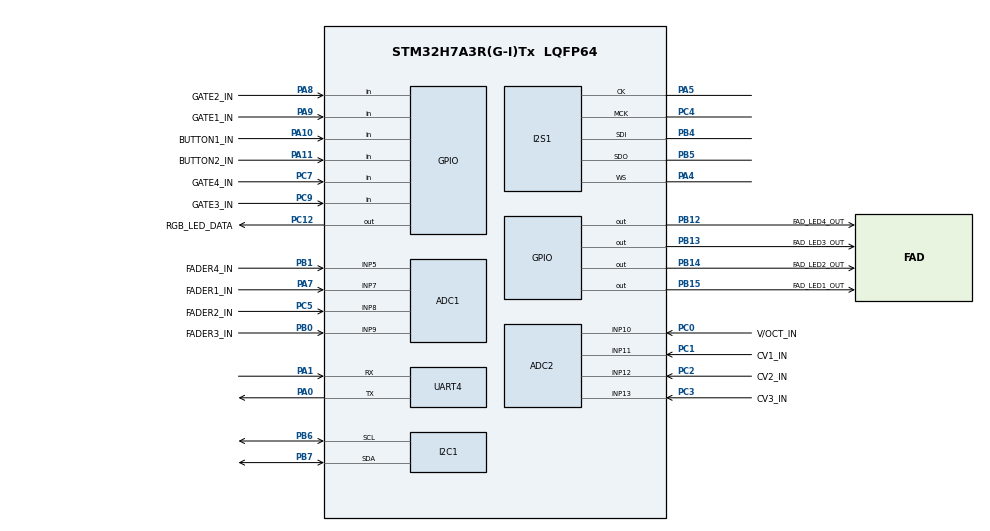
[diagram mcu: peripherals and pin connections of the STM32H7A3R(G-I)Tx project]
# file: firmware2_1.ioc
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ADC1.Channel-1\#ChannelRegularConversion=ADC_CHANNEL_7
ADC1.Channel-2\#ChannelRegularConversion=ADC_CHANNEL_8
ADC1.Channel-3\#ChannelRegularConversion=ADC_CHANNEL_9
ADC1.Channel-4\#ChannelRegularConversion=ADC_CHANNEL_5
ADC1.ClockPrescaler=ADC_CLOCK_ASYNC_DIV4
ADC1.ContinuousConvMode=ENABLE
ADC1.NbrOfConversion=4
ADC1.NbrOfConversionFlag=1
ADC1.OffsetNumber-1\#ChannelRegularConversion=ADC_OFFSET_NONE
ADC1.OffsetNumber-2\#ChannelRegularConversion=ADC_OFFSET_NONE
ADC1.OffsetNumber-3\#ChannelRegularConversion=ADC_OFFSET_NONE
ADC1.OffsetNumber-4\#ChannelRegularConversion=ADC_OFFSET_NONE
ADC1.OffsetSignedSaturation-1\#ChannelRegularConversion=DISABLE
ADC1.OffsetSignedSaturation-2\#ChannelRegularConversion=DISABLE
ADC1.OffsetSignedSaturation-3\#ChannelRegularConversion=DISABLE
ADC1.OffsetSignedSaturation-4\#ChannelRegularConversion=DISABLE
ADC1.Rank-1\#ChannelRegularConversion=1
ADC1.Rank-2\#ChannelRegularConversion=2
ADC1.Rank-3\#ChannelRegularConversion=3
ADC1.Rank-4\#ChannelRegularConversion=4
ADC1.SamplingTime-1\#ChannelRegularConversion=ADC_SAMPLETIME_1CYCLE_5
ADC1.SamplingTime-2\#ChannelRegularConversion=ADC_SAMPLETIME_1CYCLE_5
ADC1.SamplingTime-3\#ChannelRegularConversion=ADC_SAMPLETIME_1CYCLE_5
ADC1.SamplingTime-4\#ChannelRegularConversion=ADC_SAMPLETIME_1CYCLE_5
ADC1.master=1
ADC2.Channel-5\#ChannelRegularConversion=ADC_CHANNEL_10
ADC2.Channel-6\#ChannelRegularConversion=ADC_CHANNEL_11
ADC2.Channel-7\#ChannelRegularConversion=ADC_CHANNEL_12
ADC2.Channel-8\#ChannelRegularConversion=ADC_CHANNEL_13
ADC2.ContinuousConvMode=ENABLE
ADC2.NbrOfConversion=4
ADC2.NbrOfConversionFlag=1
ADC2.OffsetNumber-5\#ChannelRegularConversion=ADC_OFFSET_NONE
ADC2.OffsetNumber-6\#ChannelRegularConversion=ADC_OFFSET_NONE
ADC2.OffsetNumber-7\#ChannelRegularConversion=ADC_OFFSET_NONE
ADC2.OffsetNumber-8\#ChannelRegularConversion=ADC_OFFSET_NONE
ADC2.OffsetSignedSaturation-5\#ChannelRegularConversion=DISABLE
ADC2.OffsetSignedSaturation-6\#ChannelRegularConversion=DISABLE
ADC2.OffsetSignedSaturation-7\#ChannelRegularConversion=DISABLE
ADC2.OffsetSignedSaturation-8\#ChannelRegularConversion=DISABLE
ADC2.Rank-5\#ChannelRegularConversion=1
ADC2.Rank-6\#ChannelRegularConversion=2
ADC2.Rank-7\#ChannelRegularConversion=3
ADC2.Rank-8\#ChannelRegularConversion=4
ADC2.SamplingTime-5\#ChannelRegularConversion=ADC_SAMPLETIME_1CYCLE_5
ADC2.SamplingTime-6\#ChannelRegularConversion=ADC_SAMPLETIME_1CYCLE_5
ADC2.SamplingTime-7\#ChannelRegularConversion=ADC_SAMPLETIME_1CYCLE_5
ADC2.SamplingTime-8\#ChannelRegularConversion=ADC_SAMPLETIME_1CYCLE_5
CORTEX_M7.default_mode_Activation=1
Dma.ADC1.2.Direction=DMA_PERIPH_TO_MEMORY
Dma.ADC1.2.EventEnable=DISABLE
Dma.ADC1.2.FIFOMode=DMA_FIFOMODE_DISABLE
Dma.ADC1.2.Instance=DMA1_Stream2
Dma.ADC1.2.MemDataAlignment=DMA_MDATAALIGN_HALFWORD
Dma.ADC1.2.MemInc=DMA_MINC_ENABLE
Dma.ADC1.2.Mode=DMA_CIRCULAR
Dma.ADC1.2.PeriphDataAlignment=DMA_PDATAALIGN_HALFWORD
Dma.ADC1.2.PeriphInc=DMA_PINC_DISABLE
Dma.ADC1.2.Polarity=HAL_DMAMUX_REQ_GEN_RISING
Dma.ADC1.2.Priority=DMA_PRIORITY_LOW
Dma.ADC1.2.RequestNumber=1
Dma.ADC1.2.SignalID=NONE
Dma.ADC1.2.SyncEnable=DISABLE
Dma.ADC1.2.SyncPolarity=HAL_DMAMUX_SYNC_NO_EVENT
Dma.ADC1.2.SyncRequestNumber=1
Dma.ADC1.2.SyncSignalID=NONE
Dma.ADC2.3.Direction=DMA_PERIPH_TO_MEMORY
Dma.ADC2.3.EventEnable=DISABLE
Dma.ADC2.3.FIFOMode=DMA_FIFOMODE_DISABLE
Dma.ADC2.3.Instance=DMA1_Stream3
Dma.ADC2.3.MemDataAlignment=DMA_MDATAALIGN_HALFWORD
Dma.ADC2.3.MemInc=DMA_MINC_ENABLE
Dma.ADC2.3.Mode=DMA_NORMAL
Dma.ADC2.3.PeriphDataAlignment=DMA_PDATAALIGN_HALFWORD
Dma.ADC2.3.PeriphInc=DMA_PINC_DISABLE
Dma.ADC2.3.Polarity=HAL_DMAMUX_REQ_GEN_RISING
Dma.ADC2.3.Priority=DMA_PRIORITY_LOW
Dma.ADC2.3.RequestNumber=1
Dma.ADC2.3.SignalID=NONE
Dma.ADC2.3.SyncEnable=DISABLE
Dma.ADC2.3.SyncPolarity=HAL_DMAMUX_SYNC_NO_EVENT
Dma.ADC2.3.SyncRequestNumber=1
Dma.ADC2.3.SyncSignalID=NONE
Dma.Request0=SPI1_RX
Dma.Request1=SPI1_TX
Dma.Request2=ADC1
Dma.Request3=ADC2
Dma.SPI1_RX.0.Direction=DMA_PERIPH_TO_MEMORY
Dma.SPI1_RX.0.EventEnable=DISABLE
Dma.SPI1_RX.0.FIFOMode=DMA_FIFOMODE_DISABLE
Dma.SPI1_RX.0.Instance=DMA1_Stream0
Dma.SPI1_RX.0.MemDataAlignment=DMA_MDATAALIGN_HALFWORD
Dma.SPI1_RX.0.MemInc=DMA_MINC_ENABLE
Dma.SPI1_RX.0.Mode=DMA_NORMAL
Dma.SPI1_RX.0.PeriphDataAlignment=DMA_PDATAALIGN_HALFWORD
Dma.SPI1_RX.0.PeriphInc=DMA_PINC_DISABLE
Dma.SPI1_RX.0.Polarity=HAL_DMAMUX_REQ_GEN_RISING
Dma.SPI1_RX.0.Priority=DMA_PRIORITY_VERY_HIGH
Dma.SPI1_RX.0.RequestNumber=1
Dma.SPI1_RX.0.SignalID=NONE
Dma.SPI1_RX.0.SyncEnable=DISABLE
Dma.SPI1_RX.0.SyncPolarity=HAL_DMAMUX_SYNC_NO_EVENT
Dma.SPI1_RX.0.SyncRequestNumber=1
Dma.SPI1_RX.0.SyncSignalID=NONE
Dma.SPI1_TX.1.Direction=DMA_MEMORY_TO_PERIPH
Dma.SPI1_TX.1.EventEnable=DISABLE
Dma.SPI1_TX.1.FIFOMode=DMA_FIFOMODE_DISABLE
Dma.SPI1_TX.1.Instance=DMA1_Stream1
Dma.SPI1_TX.1.MemDataAlignment=DMA_MDATAALIGN_HALFWORD
Dma.SPI1_TX.1.MemInc=DMA_MINC_ENABLE
Dma.SPI1_TX.1.Mode=DMA_NORMAL
Dma.SPI1_TX.1.PeriphDataAlignment=DMA_PDATAALIGN_HALFWORD
Dma.SPI1_TX.1.PeriphInc=DMA_PINC_DISABLE
Dma.SPI1_TX.1.Polarity=HAL_DMAMUX_REQ_GEN_RISING
Dma.SPI1_TX.1.Priority=DMA_PRIORITY_VERY_HIGH
Dma.SPI1_TX.1.RequestNumber=1
Dma.SPI1_TX.1.SignalID=NONE
Dma.SPI1_TX.1.SyncEnable=DISABLE
Dma.SPI1_TX.1.SyncPolarity=HAL_DMAMUX_SYNC_NO_EVENT
Dma.SPI1_TX.1.SyncRequestNumber=1
Dma.SPI1_TX.1.SyncSignalID=NONE
FREERTOS.Tasks01=defaultTask,24,128,StartDefaultTask,Default,NULL,Dynamic,NULL,NULL
I2C1.Timing=0x109096E2
I2S1.ErrorAudioFreq=0.0 %
I2S1.Instance=SPI$Index
I2S1.RealAudioFreq=8.0 KHz
Mcu.Family=STM32H7
Mcu.Name=STM32H7A3R(G-I)Tx
Mcu.Package=LQFP64
NVIC.DMA1_Stream0_IRQn=true\:5\:0\:false\:false\:true\:true\:false\:true\:true
NVIC.DMA1_Stream1_IRQn=true\:5\:0\:false\:false\:true\:true\:false\:true\:true
NVIC.DMA1_Stream2_IRQn=true\:5\:0\:false\:false\:true\:true\:false\:true\:true
NVIC.DMA1_Stream3_IRQn=true\:5\:0\:false\:false\:true\:true\:false\:true\:true
NVIC.PriorityGroup=NVIC_PRIORITYGROUP_4
NVIC.TIM7_IRQn=true\:15\:0\:false\:false\:true\:false\:false\:true\:true
NVIC.TimeBase=TIM7_IRQn
NVIC.TimeBaseIP=TIM7
PA0.Mode=Asynchronous
PA0.Signal=UART4_TX
PA1.Mode=Asynchronous
PA1.Signal=UART4_RX
PA10.GPIO_Label=BUTTON1_IN
PA10.Signal=GPIO_Input
PA11.GPIO_Label=BUTTON2_IN
PA11.Signal=GPIO_Input
PA13.Mode=Trace_Asynchronous_SW
PA13.Signal=DEBUG_JTMS-SWDIO
PA14.Mode=Trace_Asynchronous_SW
PA14.Signal=DEBUG_JTCK-SWCLK
PA4.Mode=Full_Duplex_Master
PA4.Signal=I2S1_WS
PA5.Mode=Full_Duplex_Master
PA5.Signal=I2S1_CK
PA7.GPIO_Label=FADER1_IN
PA7.Signal=ADCx_INP7
PA8.GPIO_Label=GATE2_IN
PA8.Signal=GPIO_Input
PA9.GPIO_Label=GATE1_IN
PA9.Signal=GPIO_Input
PB0.GPIO_Label=FADER3_IN
PB0.Signal=ADCx_INP9
PB1.GPIO_Label=FADER4_IN
PB1.Signal=ADCx_INP5
PB12.GPIO_Label=FAD_LED4_OUT
PB12.Signal=GPIO_Output
PB13.GPIO_Label=FAD_LED3_OUT
PB13.Signal=GPIO_Output
PB14.GPIO_Label=FAD_LED2_OUT
PB14.Signal=GPIO_Output
PB15.GPIO_Label=FAD_LED1_OUT
PB15.Signal=GPIO_Output
PB3.Mode=Trace_Asynchronous_SW
PB3.Signal=DEBUG_JTDO-SWO
PB4.Mode=Full_Duplex_Master
PB4.Signal=I2S1_SDI
PB5.Mode=Full_Duplex_Master
PB5.Signal=I2S1_SDO
PB6.Mode=I2C
PB6.Signal=I2C1_SCL
PB7.Mode=I2C
PB7.Signal=I2C1_SDA
PC0.GPIO_Label=V/OCT_IN
PC0.Signal=ADCx_INP10
PC1.GPIO_Label=CV1_IN
PC1.Signal=ADCx_INP11
PC12.GPIO_Label=RGB_LED_DATA
PC12.Signal=GPIO_Output
PC2.GPIO_Label=CV2_IN
PC2.Signal=ADCx_INP12
PC3.GPIO_Label=CV3_IN
PC3.Signal=SharedAnalog_PC3
PC4.Mode=Master_Clock_Activated
PC4.Signal=I2S1_MCK
PC5.GPIO_Label=FADER2_IN
PC5.Signal=ADCx_INP8
PC7.GPIO_Label=GATE4_IN
PC7.Signal=GPIO_Input
PC9.GPIO_Label=GATE3_IN
PC9.Signal=GPIO_Input
PH0-OSC_IN.Mode=HSE-External-Oscillator
PH0-OSC_IN.Signal=RCC_OSC_IN
PH1-OSC_OUT.Mode=HSE-External-Oscillator
PH1-OSC_OUT.Signal=RCC_OSC_OUT
ProjectManager.HeapSize=0x200
ProjectManager.StackSize=0x400
ProjectManager.TargetToolchain=CMake
RCC.ADCFreq_Value=48000000
RCC.APB1Freq_Value=76800000
RCC.APB2Freq_Value=76800000
RCC.APB3Freq_Value=76800000
RCC.APB4Freq_Value=76800000
RCC.CDPPRE=RCC_APB3_DIV2
RCC.CDPPRE1=RCC_APB1_DIV2
RCC.CDPPRE2=RCC_APB2_DIV2
RCC.CortexFreq_Value=153600000
RCC.DIVM1=5
RCC.DIVM2=2
RCC.DIVM3=24
RCC.DIVN1=64
RCC.DIVN2=12
RCC.DIVP2=3
RCC.DIVQ1=25
RCC.DIVQ2=6
RCC.HCLKFreq_Value=153600000
RCC.PLL2FRACN=0
RCC.PLLFRACN=0
RCC.PLLSourceVirtual=RCC_PLLSOURCE_HSE
RCC.SRDPPRE=RCC_APB4_DIV2
RCC.SYSCLKFreq_VALUE=153600000
RCC.SYSCLKSource=RCC_SYSCLKSOURCE_PLLCLK
RCC.USBFreq_Value=12288000
SH.ADCx_INP10.0=ADC2_INP10,IN10-Single-Ended
SH.ADCx_INP11.0=ADC2_INP11,IN11-Single-Ended
SH.ADCx_INP12.0=ADC2_INP12,IN12-Single-Ended
SH.ADCx_INP5.0=ADC1_INP5,IN5-Single-Ended
SH.ADCx_INP7.0=ADC1_INP7,IN7-Single-Ended
SH.ADCx_INP8.0=ADC1_INP8,IN8-Single-Ended
SH.ADCx_INP9.0=ADC1_INP9,IN9-Single-Ended
SH.SharedAnalog_PC3.0=ADC2_INN12
SH.SharedAnalog_PC3.1=ADC2_INP13,IN13-Single-Ended
STMicroelectronics.X-CUBE-ALGOBUILD.1.4.0.LibraryCcDSPOoLibraryJjDSPOoLibrary=true
VP_FREERTOS_VS_CMSIS_V2.Mode=CMSIS_V2
VP_MEMORYMAP_VS_MEMORYMAP.Mode=CurAppReg
VP_STMicroelectronics.X-CUBE-ALGOBUILD_VS_DSPOoLibraryJjLibrary_1.4.0_1.4.0.Mode=DSPOoLibraryJjLibrary
VP_SYS_VS_tim7.Mode=TIM7
board=custom

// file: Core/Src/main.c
/* USER CODE BEGIN Header */
/**
  ******************************************************************************
  * @file           : main.c
  * @brief          : Main program body
  ******************************************************************************
  * @attention
  *
  * Copyright (c) 2026 STMicroelectronics.
  * All rights reserved.
  *
  * This software is licensed under terms that can be found in the LICENSE file
  * in the root directory of this software component.
  * If no LICENSE file comes with this software, it is provided AS-IS.
  *
  ******************************************************************************
  */
/* USER CODE END Header */
#include "main.h"
#include "cmsis_os.h"
#include "adc.h"
#include "dma.h"
#include "i2c.h"
#include "i2s.h"
#include "usart.h"
#include "gpio.h"

/* USER CODE BEGIN Includes */
#include "audioengine.h"
#include "tlv320.h"

/* USER CODE END Includes */

void SystemClock_Config(void);
void PeriphCommonClock_Config(void);
static void MPU_Config(void);
void MX_FREERTOS_Init(void);
/* USER CODE BEGIN PFP */
void FREERTOS_Init(void);

/* USER CODE END PFP */

int main(void) {

    /* MPU Configuration--------------------------------------------------------*/
    MPU_Config();

    /* MCU Configuration--------------------------------------------------------*/

    /* Reset of all peripherals, Initializes the Flash interface and the Systick. */
    HAL_Init();

    /* Configure the system clock */
    SystemClock_Config();

    /* Configure the peripherals common clocks */
    PeriphCommonClock_Config();

    /* Initialize all configured peripherals */
    MX_GPIO_Init();
    MX_DMA_Init();
    MX_ADC1_Init();
    MX_ADC2_Init();
    MX_I2C1_Init();
    MX_I2S1_Init();
    MX_UART4_Init();
    /* USER CODE BEGIN 2 */

    // // fill sinetable
    // initSineTable();

    // generateSineWave(440);
    FREERTOS_Init();

    /* USER CODE END 2 */

    /* Init scheduler */
    osKernelInitialize(); /* Call init function for freertos objects (in cmsis_os2.c) */
    MX_FREERTOS_Init();

    /* Start scheduler */
    osKernelStart();

    /* We should never get here as control is now taken by the scheduler */

    /* Infinite loop */
    while (1) {

    }
}

void SystemClock_Config(void) {
    RCC_OscInitTypeDef RCC_OscInitStruct = {0};
    RCC_ClkInitTypeDef RCC_ClkInitStruct = {0};

    /*AXI clock gating */
    RCC->CKGAENR = 0xE003FFFF;

    /** Supply configuration update enable
  */
    HAL_PWREx_ConfigSupply(PWR_LDO_SUPPLY);

    /** Configure the main internal regulator output voltage
  */
    __HAL_PWR_VOLTAGESCALING_CONFIG(PWR_REGULATOR_VOLTAGE_SCALE2);

    while (!__HAL_PWR_GET_FLAG(PWR_FLAG_VOSRDY)) {
    }

    /** Initializes the RCC Oscillators according to the specified parameters
  * in the RCC_OscInitTypeDef structure.
  */
    RCC_OscInitStruct.OscillatorType = RCC_OSCILLATORTYPE_HSE;
    RCC_OscInitStruct.HSEState = RCC_HSE_ON;
    RCC_OscInitStruct.PLL.PLLState = RCC_PLL_ON;
    RCC_OscInitStruct.PLL.PLLSource = RCC_PLLSOURCE_HSE;
    RCC_OscInitStruct.PLL.PLLM = 5;
    RCC_OscInitStruct.PLL.PLLN = 64;
    RCC_OscInitStruct.PLL.PLLP = 2;
    RCC_OscInitStruct.PLL.PLLQ = 25;
    RCC_OscInitStruct.PLL.PLLR = 2;
    RCC_OscInitStruct.PLL.PLLRGE = RCC_PLL1VCIRANGE_2;
    RCC_OscInitStruct.PLL.PLLVCOSEL = RCC_PLL1VCOWIDE;
    RCC_OscInitStruct.PLL.PLLFRACN = 0;
    if (HAL_RCC_OscConfig(&RCC_OscInitStruct) != HAL_OK) {
        Error_Handler();
    }

    /** Initializes the CPU, AHB and APB buses clocks
  */
    RCC_ClkInitStruct.ClockType = RCC_CLOCKTYPE_HCLK | RCC_CLOCKTYPE_SYSCLK | RCC_CLOCKTYPE_PCLK1 | RCC_CLOCKTYPE_PCLK2 |
                                  RCC_CLOCKTYPE_D3PCLK1 | RCC_CLOCKTYPE_D1PCLK1;
    RCC_ClkInitStruct.SYSCLKSource = RCC_SYSCLKSOURCE_PLLCLK;
    RCC_ClkInitStruct.SYSCLKDivider = RCC_SYSCLK_DIV1;
    RCC_ClkInitStruct.AHBCLKDivider = RCC_HCLK_DIV1;
    RCC_ClkInitStruct.APB3CLKDivider = RCC_APB3_DIV2;
    RCC_ClkInitStruct.APB1CLKDivider = RCC_APB1_DIV2;
    RCC_ClkInitStruct.APB2CLKDivider = RCC_APB2_DIV2;
    RCC_ClkInitStruct.APB4CLKDivider = RCC_APB4_DIV2;

    if (HAL_RCC_ClockConfig(&RCC_ClkInitStruct, FLASH_LATENCY_4) != HAL_OK) {
        Error_Handler();
    }
}

void PeriphCommonClock_Config(void) {
    RCC_PeriphCLKInitTypeDef PeriphClkInitStruct = {0};

    /** Initializes the peripherals clock
  */
    PeriphClkInitStruct.PeriphClockSelection = RCC_PERIPHCLK_ADC;
    PeriphClkInitStruct.PLL2.PLL2M = 2;
    PeriphClkInitStruct.PLL2.PLL2N = 12;
    PeriphClkInitStruct.PLL2.PLL2P = 3;
    PeriphClkInitStruct.PLL2.PLL2Q = 6;
    PeriphClkInitStruct.PLL2.PLL2R = 2;
    PeriphClkInitStruct.PLL2.PLL2RGE = RCC_PLL2VCIRANGE_3;
    PeriphClkInitStruct.PLL2.PLL2VCOSEL = RCC_PLL2VCOWIDE;
    PeriphClkInitStruct.PLL2.PLL2FRACN = 0;
    PeriphClkInitStruct.AdcClockSelection = RCC_ADCCLKSOURCE_PLL2;
    if (HAL_RCCEx_PeriphCLKConfig(&PeriphClkInitStruct) != HAL_OK) {
        Error_Handler();
    }
}

/* MPU Configuration */

void MPU_Config(void) {
    MPU_Region_InitTypeDef MPU_InitStruct = {0};

    /* Disables the MPU */
    HAL_MPU_Disable();

    /** Initializes and configures the Region and the memory to be protected
  */
    MPU_InitStruct.Enable = MPU_REGION_ENABLE;
    MPU_InitStruct.Number = MPU_REGION_NUMBER0;
    MPU_InitStruct.BaseAddress = 0x0;
    MPU_InitStruct.Size = MPU_REGION_SIZE_4GB;
    MPU_InitStruct.SubRegionDisable = 0x87;
    MPU_InitStruct.TypeExtField = MPU_TEX_LEVEL0;
    MPU_InitStruct.AccessPermission = MPU_REGION_NO_ACCESS;
    MPU_InitStruct.DisableExec = MPU_INSTRUCTION_ACCESS_DISABLE;
    MPU_InitStruct.IsShareable = MPU_ACCESS_SHAREABLE;
    MPU_InitStruct.IsCacheable = MPU_ACCESS_NOT_CACHEABLE;
    MPU_InitStruct.IsBufferable = MPU_ACCESS_NOT_BUFFERABLE;

    HAL_MPU_ConfigRegion(&MPU_InitStruct);
    /* Enables the MPU */
    HAL_MPU_Enable(MPU_PRIVILEGED_DEFAULT);
}

void HAL_TIM_PeriodElapsedCallback(TIM_HandleTypeDef* htim) {
    if (htim->Instance == TIM7) {
        HAL_IncTick();
    }
}

void Error_Handler(void) {
    __disable_irq();
    while (1) {
    }
}

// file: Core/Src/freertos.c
/* USER CODE BEGIN Header */
/**
  ******************************************************************************
  * File Name          : freertos.c
  * Description        : Code for freertos applications
  ******************************************************************************
  * @attention
  *
  * Copyright (c) 2026 STMicroelectronics.
  * All rights reserved.
  *
  * This software is licensed under terms that can be found in the LICENSE file
  * in the root directory of this software component.
  * If no LICENSE file comes with this software, it is provided AS-IS.
  *
  ******************************************************************************
  */
/* USER CODE END Header */

#include "FreeRTOS.h"
#include "task.h"
#include "main.h"
#include "cmsis_os.h"

/* USER CODE BEGIN Includes */
#include <stdbool.h>

#include "tlv320.h"
#include "audioengine.h"
#include "tape_player.h"
/* USER CODE END Includes */

/* Definitions for defaultTask */
osThreadId_t defaultTaskHandle;
const osThreadAttr_t defaultTask_attributes = {
  .name = "defaultTask",
  .stack_size = 128 * 4,
  .priority = (osPriority_t) osPriorityNormal,
};

void StartDefaultTask(void *argument);

void MX_FREERTOS_Init(void); /* (MISRA C 2004 rule 8.1) */

void MX_FREERTOS_Init(void) {

  /* Create the thread(s) */
  /* creation of defaultTask */
  defaultTaskHandle = osThreadNew(StartDefaultTask, NULL, &defaultTask_attributes);

}

void StartDefaultTask(void *argument)
{
  for(;;)
  {
    osDelay(1);
  }
}
